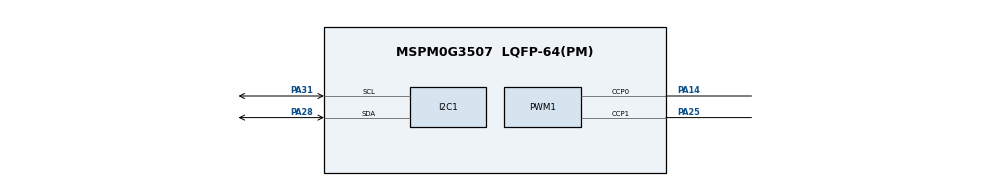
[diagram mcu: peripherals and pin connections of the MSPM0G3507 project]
/**
 * These arguments were used when this file was generated. They will be automatically applied on subsequent loads
 * via the GUI or CLI. Run CLI with '--help' for additional information on how to override these arguments.
 * @cliArgs --device "MSPM0G350X" --part "Default" --package "LQFP-64(PM)" --product "mspm0_sdk@2.04.00.06"
 * @v2CliArgs --device "MSPM0G3507" --package "LQFP-64(PM)" --product "mspm0_sdk@2.04.00.06"
 * @versions {"tool":"1.22.0+3893"}
 */

/**
 * Import the modules used in this configuration.
 */
const GPIO          = scripting.addModule("/ti/driverlib/GPIO", {}, false);
const GPIO1         = GPIO.addInstance();
const GPIO2         = GPIO.addInstance();
const GPIO3         = GPIO.addInstance();
const GPIO4         = GPIO.addInstance();
const GPIO5         = GPIO.addInstance();
const GPIO6         = GPIO.addInstance();
const I2C           = scripting.addModule("/ti/driverlib/I2C", {}, false);
const I2C1          = I2C.addInstance();
const PWM           = scripting.addModule("/ti/driverlib/PWM", {}, false);
const PWM1          = PWM.addInstance();
const SYSCTL        = scripting.addModule("/ti/driverlib/SYSCTL");
const SYSTICK       = scripting.addModule("/ti/driverlib/SYSTICK");
const TIMER         = scripting.addModule("/ti/driverlib/TIMER", {}, false);
const TIMER1        = TIMER.addInstance();
const TIMER2        = TIMER.addInstance();
const TIMER3        = TIMER.addInstance();
const ProjectConfig = scripting.addModule("/ti/project_config/ProjectConfig");

/**
 * Write custom configuration values to the imported modules.
 */
GPIO1.$name                          = "Motor";
GPIO1.associatedPins.create(8);
GPIO1.associatedPins[0].$name        = "PIN_AIN1";
GPIO1.associatedPins[0].assignedPin  = "8";
GPIO1.associatedPins[0].assignedPort = "PORTA";
GPIO1.associatedPins[1].$name        = "PIN_AIN2";
GPIO1.associatedPins[1].assignedPin  = "9";
GPIO1.associatedPins[1].assignedPort = "PORTA";
GPIO1.associatedPins[2].$name        = "PIN_BIN1";
GPIO1.associatedPins[2].assignedPin  = "13";
GPIO1.associatedPins[2].assignedPort = "PORTA";
GPIO1.associatedPins[3].$name        = "PIN_BIN2";
GPIO1.associatedPins[3].assignedPin  = "16";
GPIO1.associatedPins[3].assignedPort = "PORTA";
GPIO1.associatedPins[4].$name        = "E2B";
GPIO1.associatedPins[4].assignedPin  = "12";
GPIO1.associatedPins[4].assignedPort = "PORTA";
GPIO1.associatedPins[5].$name        = "E2A";
GPIO1.associatedPins[5].assignedPort = "PORTA";
GPIO1.associatedPins[5].assignedPin  = "15";
GPIO1.associatedPins[6].$name        = "E1A";
GPIO1.associatedPins[6].assignedPort = "PORTA";
GPIO1.associatedPins[6].assignedPin  = "21";
GPIO1.associatedPins[7].$name        = "E1B";
GPIO1.associatedPins[7].assignedPort = "PORTA";
GPIO1.associatedPins[7].assignedPin  = "22";

const Board = scripting.addModule("/ti/driverlib/Board", {}, false);

GPIO2.port                          = "PORTA";
GPIO2.$name                         = "MPU";
GPIO2.associatedPins.create(2);
GPIO2.associatedPins[0].assignedPin = "0";
GPIO2.associatedPins[0].$name       = "MPU_SDA";
GPIO2.associatedPins[1].assignedPin = "1";
GPIO2.associatedPins[1].$name       = "MPU_SCL";

GPIO3.$name                              = "KEY";
GPIO3.associatedPins.create(3);
GPIO3.associatedPins[0].$name            = "KEY_1";
GPIO3.associatedPins[0].assignedPort     = "PORTB";
GPIO3.associatedPins[0].assignedPin      = "9";
GPIO3.associatedPins[0].internalResistor = "PULL_UP";
GPIO3.associatedPins[0].direction        = "INPUT";
GPIO3.associatedPins[1].internalResistor = "PULL_UP";
GPIO3.associatedPins[1].assignedPort     = "PORTB";
GPIO3.associatedPins[1].assignedPin      = "8";
GPIO3.associatedPins[1].$name            = "KEY_2";
GPIO3.associatedPins[1].direction        = "INPUT";
GPIO3.associatedPins[2].$name            = "KEY_3";
GPIO3.associatedPins[2].assignedPort     = "PORTA";
GPIO3.associatedPins[2].assignedPin      = "7";
GPIO3.associatedPins[2].internalResistor = "PULL_UP";
GPIO3.associatedPins[2].direction        = "INPUT";

GPIO4.port                          = "PORTB";
GPIO4.$name                         = "USOUND";
GPIO4.associatedPins.create(2);
GPIO4.associatedPins[0].$name       = "Trig";
GPIO4.associatedPins[0].assignedPin = "19";
GPIO4.associatedPins[1].$name       = "Echo";
GPIO4.associatedPins[1].assignedPin = "18";
GPIO4.associatedPins[1].direction   = "INPUT";
GPIO4.associatedPins[1].interruptEn = true;
GPIO4.associatedPins[1].polarity    = "RISE_FALL";

GPIO5.$name                         = "BUZ";
GPIO5.port                          = "PORTA";
GPIO5.associatedPins[0].$name       = "Buz";
GPIO5.associatedPins[0].assignedPin = "17";

GPIO6.$name                              = "LED";
GPIO6.associatedPins.create(3);
GPIO6.associatedPins[0].$name            = "LED1";
GPIO6.associatedPins[0].assignedPin      = "2";
GPIO6.associatedPins[0].assignedPort     = "PORTA";
GPIO6.associatedPins[0].internalResistor = "PULL_UP";
GPIO6.associatedPins[0].initialValue     = "SET";
GPIO6.associatedPins[1].$name            = "LED2";
GPIO6.associatedPins[1].assignedPort     = "PORTB";
GPIO6.associatedPins[1].assignedPin      = "24";
GPIO6.associatedPins[1].internalResistor = "PULL_UP";
GPIO6.associatedPins[1].initialValue     = "SET";
GPIO6.associatedPins[2].$name            = "LED3";
GPIO6.associatedPins[2].assignedPin      = "20";
GPIO6.associatedPins[2].assignedPort     = "PORTB";
GPIO6.associatedPins[2].internalResistor = "PULL_UP";
GPIO6.associatedPins[2].initialValue     = "SET";

I2C1.$name                             = "I2C_OLED";
I2C1.basicEnableController             = true;
I2C1.intController                     = ["ARBITRATION_LOST","NACK","RXFIFO_TRIGGER","RX_DONE","TX_DONE"];
I2C1.basicControllerStandardBusSpeed   = "FastPlus";
I2C1.basicControllerBusSpeedArray      = -2;
I2C1.peripheral.sdaPin.$assign         = "PA28";
I2C1.peripheral.sclPin.$assign         = "PA31";
I2C1.sdaPinConfig.hideOutputInversion  = scripting.forceWrite(false);
I2C1.sdaPinConfig.onlyInternalResistor = scripting.forceWrite(false);
I2C1.sdaPinConfig.passedPeripheralType = scripting.forceWrite("Digital");
I2C1.sdaPinConfig.$name                = "ti_driverlib_gpio_GPIOPinGeneric2";
I2C1.sclPinConfig.hideOutputInversion  = scripting.forceWrite(false);
I2C1.sclPinConfig.onlyInternalResistor = scripting.forceWrite(false);
I2C1.sclPinConfig.passedPeripheralType = scripting.forceWrite("Digital");
I2C1.sclPinConfig.$name                = "ti_driverlib_gpio_GPIOPinGeneric3";

PWM1.timerCount                         = 10000;
PWM1.$name                              = "PWM_Motor";
PWM1.timerStartTimer                    = true;
PWM1.peripheral.ccp0Pin.$assign         = "PA14";
PWM1.peripheral.ccp1Pin.$assign         = "PA25";
PWM1.PWM_CHANNEL_0.$name                = "ti_driverlib_pwm_PWMTimerCC0";
PWM1.PWM_CHANNEL_1.$name                = "ti_driverlib_pwm_PWMTimerCC1";
PWM1.ccp0PinConfig.direction            = scripting.forceWrite("OUTPUT");
PWM1.ccp0PinConfig.hideOutputInversion  = scripting.forceWrite(false);
PWM1.ccp0PinConfig.onlyInternalResistor = scripting.forceWrite(false);
PWM1.ccp0PinConfig.passedPeripheralType = scripting.forceWrite("Digital");
PWM1.ccp0PinConfig.$name                = "ti_driverlib_gpio_GPIOPinGeneric0";
PWM1.ccp1PinConfig.direction            = scripting.forceWrite("OUTPUT");
PWM1.ccp1PinConfig.hideOutputInversion  = scripting.forceWrite(false);
PWM1.ccp1PinConfig.onlyInternalResistor = scripting.forceWrite(false);
PWM1.ccp1PinConfig.passedPeripheralType = scripting.forceWrite("Digital");
PWM1.ccp1PinConfig.$name                = "ti_driverlib_gpio_GPIOPinGeneric1";

SYSCTL.forceDefaultClkConfig = true;
SYSCTL.clockTreeEn           = true;

SYSTICK.periodEnable  = true;
SYSTICK.systickEnable = true;
SYSTICK.period        = 320;

TIMER1.timerClkPrescale   = 32;
TIMER1.timerMode          = "ONE_SHOT_UP";
TIMER1.$name              = "TIMER_USOUND";
TIMER1.interruptPriority  = "0";
TIMER1.interrupts         = ["LOAD"];
TIMER1.timerPeriod        = "20ms";
TIMER1.peripheral.$assign = "TIMG0";

TIMER2.$name              = "TIMER_0";
TIMER2.timerMode          = "PERIODIC";
TIMER2.interrupts         = ["ZERO"];
TIMER2.timerStartTimer    = true;
TIMER2.timerPeriod        = "14 ms";
TIMER2.timerClkPrescale   = 8;
TIMER2.peripheral.$assign = "TIMG7";

TIMER3.$name              = "TIMER_1";
TIMER3.timerClkDiv        = 8;
TIMER3.timerMode          = "PERIODIC";
TIMER3.interrupts         = ["ZERO"];
TIMER3.timerStartTimer    = true;
TIMER3.timerClkPrescale   = 20;
TIMER3.timerPeriod        = "100 ms";
TIMER3.peripheral.$assign = "TIMG6";

ProjectConfig.genLibDrivers = true;

/**
 * Pinmux solution for unlocked pins/peripherals. This ensures that minor changes to the automatic solver in a future
 * version of the tool will not impact the pinmux you originally saw.  These lines can be completely deleted in order to
 * re-solve from scratch.
 */
GPIO1.associatedPins[0].pin.$suggestSolution = "PA8";
GPIO1.associatedPins[1].pin.$suggestSolution = "PA9";
GPIO1.associatedPins[2].pin.$suggestSolution = "PA13";
GPIO1.associatedPins[3].pin.$suggestSolution = "PA16";
GPIO1.associatedPins[4].pin.$suggestSolution = "PA12";
GPIO1.associatedPins[5].pin.$suggestSolution = "PA15";
GPIO1.associatedPins[6].pin.$suggestSolution = "PA21";
GPIO1.associatedPins[7].pin.$suggestSolution = "PA22";
Board.peripheral.$suggestSolution            = "DEBUGSS";
Board.peripheral.swclkPin.$suggestSolution   = "PA20";
Board.peripheral.swdioPin.$suggestSolution   = "PA19";
GPIO2.associatedPins[0].pin.$suggestSolution = "PA0";
GPIO2.associatedPins[1].pin.$suggestSolution = "PA1";
GPIO3.associatedPins[0].pin.$suggestSolution = "PB9";
GPIO3.associatedPins[1].pin.$suggestSolution = "PB8";
GPIO3.associatedPins[2].pin.$suggestSolution = "PA7";
GPIO4.associatedPins[0].pin.$suggestSolution = "PB19";
GPIO4.associatedPins[1].pin.$suggestSolution = "PB18";
GPIO5.associatedPins[0].pin.$suggestSolution = "PA17";
GPIO6.associatedPins[0].pin.$suggestSolution = "PA2";
GPIO6.associatedPins[1].pin.$suggestSolution = "PB24";
GPIO6.associatedPins[2].pin.$suggestSolution = "PB20";
I2C1.peripheral.$suggestSolution             = "I2C0";
PWM1.peripheral.$suggestSolution             = "TIMG12";
